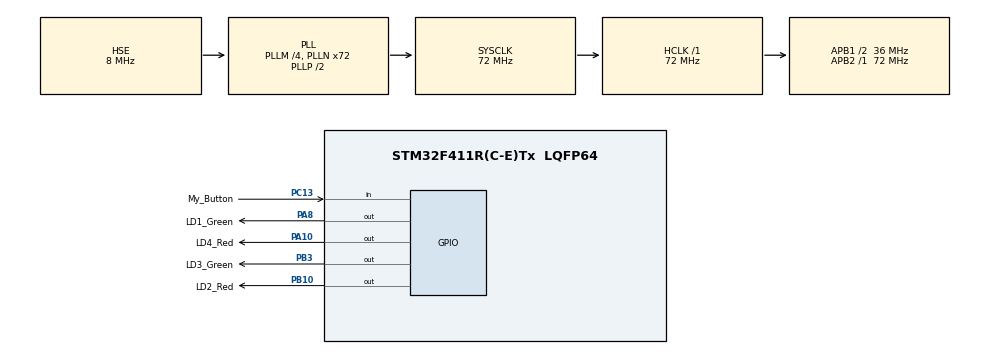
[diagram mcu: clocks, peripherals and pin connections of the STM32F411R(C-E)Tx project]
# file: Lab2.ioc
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Mcu.Family=STM32F4
Mcu.Name=STM32F411R(C-E)Tx
Mcu.Package=LQFP64
NVIC.PriorityGroup=NVIC_PRIORITYGROUP_0
PA10.GPIO_Label=LD4_Red
PA10.Signal=GPIO_Output
PA13.GPIO_Label=TMS
PA13.Mode=Serial_Wire
PA13.Signal=SYS_JTMS-SWDIO
PA14.GPIO_Label=TCK
PA14.Mode=Serial_Wire
PA14.Signal=SYS_JTCK-SWCLK
PA8.GPIO_Label=LD1_Green
PA8.GPIO_PuPd=GPIO_NOPULL
PA8.Signal=GPIO_Output
PB10.GPIO_Label=LD2_Red
PB10.GPIO_PuPd=GPIO_NOPULL
PB10.Signal=GPIO_Output
PB3.GPIO_Label=LD3_Green
PB3.Signal=GPIO_Output
PC13-ANTI_TAMP.GPIO_Label=My_Button
PC13-ANTI_TAMP.GPIO_PuPd=GPIO_NOPULL
PC13-ANTI_TAMP.Signal=GPIO_Input
PC14-OSC32_IN.Signal=RCC_OSC32_IN
PC15-OSC32_OUT.Signal=RCC_OSC32_OUT
PH0\ -\ OSC_IN.Mode=HSE-External-Oscillator
PH0\ -\ OSC_IN.Signal=RCC_OSC_IN
PH1\ -\ OSC_OUT.Mode=HSE-External-Oscillator
PH1\ -\ OSC_OUT.Signal=RCC_OSC_OUT
ProjectManager.HeapSize=0x200
ProjectManager.StackSize=0x400
ProjectManager.TargetToolchain=STM32CubeIDE
RCC.48MHZClocksFreq_Value=36000000
RCC.AHBFreq_Value=72000000
RCC.APB1CLKDivider=RCC_HCLK_DIV2
RCC.APB1Freq_Value=36000000
RCC.APB1TimFreq_Value=72000000
RCC.APB2Freq_Value=72000000
RCC.APB2TimFreq_Value=72000000
RCC.CortexFreq_Value=72000000
RCC.FLatency-AdvancedSettings=FLASH_LATENCY_2
RCC.HCLKFreq_Value=72000000
RCC.HSE_VALUE=8000000
RCC.HSI_VALUE=16000000
RCC.LSE_VALUE=32768
RCC.PLLM=4
RCC.PLLN=72
RCC.PLLSourceVirtual=RCC_PLLSOURCE_HSE
RCC.SYSCLKFreq_VALUE=72000000
RCC.SYSCLKSource=RCC_SYSCLKSOURCE_PLLCLK
RCC.VCOOutputFreq_Value=144000000
board=NUCLEO-F411RE

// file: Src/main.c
/* USER CODE BEGIN Header */
/**
  ******************************************************************************
  * @file           : main.c
  * @brief          : Main program body
  ******************************************************************************
  * @attention
  *
  * Copyright (c) 2023 STMicroelectronics.
  * All rights reserved.
  *
  * This software is licensed under terms that can be found in the LICENSE file
  * in the root directory of this software component.
  * If no LICENSE file comes with this software, it is provided AS-IS.
  *
  ******************************************************************************
  */
/* USER CODE END Header */
#include "main.h"

void SystemClock_Config(void);
static void MX_GPIO_Init(void);

/* USER CODE BEGIN 0 */
// Змінити стан світлодіодів (вмикання/вимикання по черзі)
void LED_Toggle(void) {
  static GPIO_TypeDef *ledPorts[] = {GPIOA, GPIOB, GPIOB, GPIOA};
  static uint16_t ledPins[] = {LD1_Green_Pin, LD2_Red_Pin, LD3_Green_Pin, LD4_Red_Pin};
  static uint8_t currentLed = 0;

  // Вимикаємо всі світлодіоди
  HAL_GPIO_WritePin(GPIOA, LD1_Green_Pin, GPIO_PIN_RESET);
  HAL_GPIO_WritePin(GPIOB, LD2_Red_Pin, GPIO_PIN_RESET);
  HAL_GPIO_WritePin(GPIOB, LD3_Green_Pin, GPIO_PIN_RESET);
  HAL_GPIO_WritePin(GPIOA, LD4_Red_Pin, GPIO_PIN_RESET);

  // Вмикаємо поточний світлодіод
  HAL_GPIO_WritePin(ledPorts[currentLed], ledPins[currentLed], GPIO_PIN_SET);

  // Збільшуємо лічильник світлодіодів ділимо на 4 щоб коли значення доходило до 4 воно обнулялось
  currentLed = (currentLed + 1) % 4;
}
/* USER CODE END 0 */

int main(void)
{

  /* MCU Configuration--------------------------------------------------------*/

  /* Reset of all peripherals, Initializes the Flash interface and the Systick. */
  HAL_Init();

  /* Configure the system clock */
  SystemClock_Config();

  /* Initialize all configured peripherals */
  MX_GPIO_Init();

  /* Infinite loop */
  /* USER CODE BEGIN WHILE */
  while (1)
  {
	  // Перевірка стану кнопки
	  GPIO_PinState buttonState = HAL_GPIO_ReadPin(My_Button_GPIO_Port, My_Button_Pin);

	  // Якщо кнопка натиснута, вмикаємо світлодіоди по черзі
	  if (buttonState == GPIO_PIN_RESET) {
	        LED_Toggle();
	        HAL_Delay(300);  // Затримка для уникнення багаторазового натискання кнопки
	  }
    /* USER CODE END WHILE */

  }
}

void SystemClock_Config(void)
{
  RCC_OscInitTypeDef RCC_OscInitStruct = {0};
  RCC_ClkInitTypeDef RCC_ClkInitStruct = {0};

  /** Configure the main internal regulator output voltage
  */
  __HAL_RCC_PWR_CLK_ENABLE();
  __HAL_PWR_VOLTAGESCALING_CONFIG(PWR_REGULATOR_VOLTAGE_SCALE1);

  /** Initializes the RCC Oscillators according to the specified parameters
  * in the RCC_OscInitTypeDef structure.
  */
  RCC_OscInitStruct.OscillatorType = RCC_OSCILLATORTYPE_HSE;
  RCC_OscInitStruct.HSEState = RCC_HSE_ON;
  RCC_OscInitStruct.PLL.PLLState = RCC_PLL_ON;
  RCC_OscInitStruct.PLL.PLLSource = RCC_PLLSOURCE_HSE;
  RCC_OscInitStruct.PLL.PLLM = 4;
  RCC_OscInitStruct.PLL.PLLN = 72;
  RCC_OscInitStruct.PLL.PLLP = RCC_PLLP_DIV2;
  RCC_OscInitStruct.PLL.PLLQ = 4;
  if (HAL_RCC_OscConfig(&RCC_OscInitStruct) != HAL_OK)
  {
    Error_Handler();
  }

  /** Initializes the CPU, AHB and APB buses clocks
  */
  RCC_ClkInitStruct.ClockType = RCC_CLOCKTYPE_HCLK|RCC_CLOCKTYPE_SYSCLK
                              |RCC_CLOCKTYPE_PCLK1|RCC_CLOCKTYPE_PCLK2;
  RCC_ClkInitStruct.SYSCLKSource = RCC_SYSCLKSOURCE_PLLCLK;
  RCC_ClkInitStruct.AHBCLKDivider = RCC_SYSCLK_DIV1;
  RCC_ClkInitStruct.APB1CLKDivider = RCC_HCLK_DIV2;
  RCC_ClkInitStruct.APB2CLKDivider = RCC_HCLK_DIV1;

  if (HAL_RCC_ClockConfig(&RCC_ClkInitStruct, FLASH_LATENCY_2) != HAL_OK)
  {
    Error_Handler();
  }
}

static void MX_GPIO_Init(void)
{
  GPIO_InitTypeDef GPIO_InitStruct = {0};

  /* GPIO Ports Clock Enable */
  __HAL_RCC_GPIOC_CLK_ENABLE();
  __HAL_RCC_GPIOH_CLK_ENABLE();
  __HAL_RCC_GPIOB_CLK_ENABLE();
  __HAL_RCC_GPIOA_CLK_ENABLE();

  /*Configure GPIO pin Output Level */
  HAL_GPIO_WritePin(GPIOB, LD2_Red_Pin|LD3_Green_Pin, GPIO_PIN_RESET);

  /*Configure GPIO pin Output Level */
  HAL_GPIO_WritePin(GPIOA, LD1_Green_Pin|LD4_Red_Pin, GPIO_PIN_RESET);

  /*Configure GPIO pin : My_Button_Pin */
  GPIO_InitStruct.Pin = My_Button_Pin;
  GPIO_InitStruct.Mode = GPIO_MODE_INPUT;
  GPIO_InitStruct.Pull = GPIO_NOPULL;
  HAL_GPIO_Init(My_Button_GPIO_Port, &GPIO_InitStruct);

  /*Configure GPIO pins : LD2_Red_Pin LD3_Green_Pin */
  GPIO_InitStruct.Pin = LD2_Red_Pin|LD3_Green_Pin;
  GPIO_InitStruct.Mode = GPIO_MODE_OUTPUT_PP;
  GPIO_InitStruct.Pull = GPIO_NOPULL;
  GPIO_InitStruct.Speed = GPIO_SPEED_FREQ_LOW;
  HAL_GPIO_Init(GPIOB, &GPIO_InitStruct);

  /*Configure GPIO pins : LD1_Green_Pin LD4_Red_Pin */
  GPIO_InitStruct.Pin = LD1_Green_Pin|LD4_Red_Pin;
  GPIO_InitStruct.Mode = GPIO_MODE_OUTPUT_PP;
  GPIO_InitStruct.Pull = GPIO_NOPULL;
  GPIO_InitStruct.Speed = GPIO_SPEED_FREQ_LOW;
  HAL_GPIO_Init(GPIOA, &GPIO_InitStruct);

}

void Error_Handler(void)
{
  __disable_irq();
  while (1)
  {
  }
}
